# H616 register map
Vendor: Allwinner; Series: H616; File version: 0.1
CPU: other 0, little endian, MPU, no FPU, 0 interrupt priority bits
Registers are 32-bit, read-write, reset 0x0 unless marked. A register's access mark holds for its fields unless they carry their own. Offsets are from the block's base; [hi:lo] are bit positions; {n}, {i} and the like mark numbered series; 'fields as' and 'values as' point back to an identical list.

## RTC
Base 0x07000000
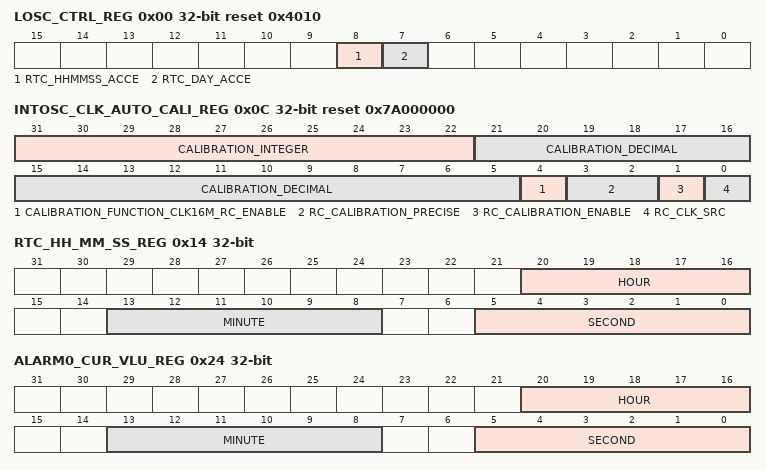
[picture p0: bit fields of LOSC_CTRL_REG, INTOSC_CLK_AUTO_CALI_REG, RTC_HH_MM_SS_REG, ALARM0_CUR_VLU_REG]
0x00 LOSC_CTRL_REG reset 0x4010 — Low Oscillator Control Register
  [8] RTC_HHMMSS_ACCE — RTC HH-MM-SS access After writing the RTC HH-MM-SS Register, this bit is set and it will be cleared until the real writing operation is finished. After writing the RTC HH-MM-SS Register, the RTC HH-MM-SS Register will be refreshed for at most one second.
  [7] RTC_DAY_ACCE — RTC DAY access After writing the RTC DAY register, this bit is set and it will be cleared until the real writing operation is finished. After writing the RTC DAY register, the DAY register will be refreshed for at most one second.
0x08 INTOSC_CLK_PRESCAL_REG reset 0xF — Internal OSC Clock Prescalar Register
  [4:0] INTOSC_32K_CLK_PRESCAL — Internal OSC 32K Clock Prescalar value N. The clock output = Internal RC/32/N. 00000: 1 00001: 2 00002: 3 ...... 11111: 32
    0=_1; 1=_2; 2=_3; 31=_32
0x0C INTOSC_CLK_AUTO_CALI_REG reset 0x7A000000 — Internal OSC Clock Auto Calibration Register
  [31:22] CALIBRATION_INTEGER ro — 32k calibration integer divider factor
  [21:5] CALIBRATION_DECIMAL ro — 32k calibration decimal divider factor
  [4] CALIBRATION_FUNCTION_CLK16M_RC_ENABLE — Calibration function Clk16M_RC_enable 0: Auto gating 1: Soft bypass
    0=Auto gating; 1=Soft bypass
  [3:2] RC_CALIBRATION_PRECISE — RC Calibration Precise Selection 00: 1ms calibration precise 01: 16ms calibration precise 10: 128ms calibration precise
    0=1ms calibration precise; 1=16ms calibration precise; 2=128ms calibration precise
  [1] RC_CALIBRATION_ENABLE — RC Calibration Enable 0: Close Calibration circuit 1: Open Calibration circuit
    0=Close Calibration circuit; 1=Open Calibration circuit
  [0] RC_CLK_SRC — RC CLK SRC SEL Select the RTC 32k clock source from normal RC or Calibrated RC 0: Normal RC 1: Calibrated RC
    0=Normal RC; 1=Calibrated RC
0x10 RTC_DAY_REG reset not defined — RTC Year-Month-Day Register
  [15:0] DAY — Day Range from 0~65535.
0x14 RTC_HH_MM_SS_REG reset not defined — RTC Hour-Minute-Second Register
  [20:16] HOUR — Range from 0~23
  [13:8] MINUTE — Range from 0~59
  [5:0] SECOND — Range from 0~59
0x20 ALARM0_COUNTER_REG — Alarm 0 Counter Register
  [15:0] ALARM0_COUNTER — Alarm 0 Counter is based on Day.
0x24 ALARM0_CUR_VLU_REG reset not defined — Alarm 0 Counter Current Value Register
  fields as RTC_HH_MM_SS_REG
0x28 ALARM0_ENABLE_REG — Alarm 0 Enable Register
  [0] ALM_0_EN — Alarm 0 Enable If this bit is set to `1`, the valid bits of Alarm 0 Counter Register will down count to zero, and the alarm pending bit will be set to `1`. 0: Disable 1: Enable
    0=Disable; 1=Enable
0x2C ALARM0_IRQ_EN — Alarm 0 IRQ Enable Register
  [0] ALARM0_IRQ_EN — Alarm 0 IRQ Enable 0: Disable 1: Enable
    0=Disable; 1=Enable
0x30 ALARM0_IRQ_STA_REG — Alarm 0 IRQ Status Register
  [0] ALARM0_IRQ_PEND write-1-clears — Alarm 0 IRQ Pending bit 0: No effect 1: Pending, alarm 0 counter value is reached If alarm 0 irq enable is set to 1, the pending bit will be sent to the interrupt controller.
    0=No_effect; 1=Pending, alarm 0 counter value is reached If alarm 0 irq enable is set to 1, the pending bit will be sent to the interrupt controller
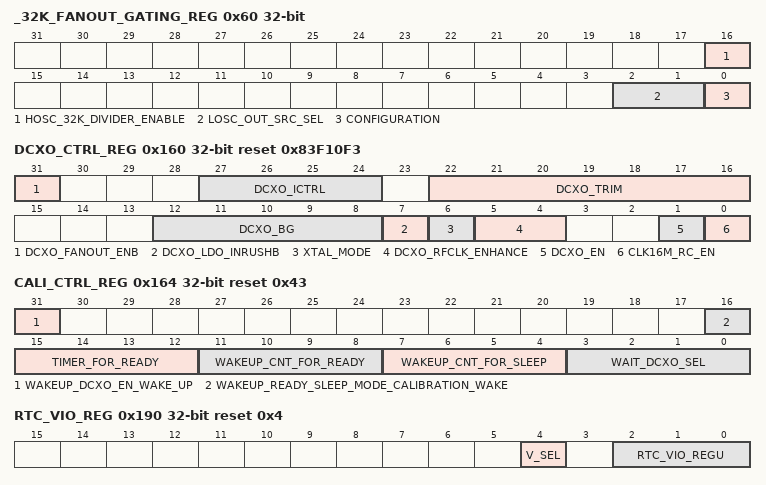
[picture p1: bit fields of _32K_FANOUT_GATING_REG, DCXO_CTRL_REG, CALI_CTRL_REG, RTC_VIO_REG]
0x60 _32K_FANOUT_GATING_REG
  [16] HOSC_32K_DIVIDER_ENABLE — HOSC_32K_DIVIDER_ENABLE 1: enable the hosc 24m to 32k divider circuit 0: disable the hosc 24m to 32k divider circuit
    1=enable the hosc 24m to 32k divider circuit; 0=disable the hosc 24m to 32k divider circuit
  [2:1] LOSC_OUT_SRC_SEL — LOSC_OUT_SRC_SEL 00:RTC_32K(select by RC_CLK_SRC_SEL) 01: Peripll divided 32K 10: HOSC divided 32K
    1=Peripll divided 32K; 2=HOSC (HOSC divided 32K)
  [0] CONFIGURATION — 32K_FANOUT_GATING Configuration of 32k output, and no 32k output by default. 0: Mask LOSC output gating 1: Enable LOSC output gating
    0=Mask LOSC output gating; 1=Enable LOSC output gating
{0x100+4i} GP_DATA_REGN[{i}] (i=0..15) — GP_DATA_REGN[{i}]
  [31:0] GP_DATA — Data [31:0]
0x160 DCXO_CTRL_REG reset 0x83F10F3 — DCXO Control Register
  [31] DCXO_FANOUT_ENB — 0: enable DCXO wake up function 1: disable DCXO wake up function
    0=enable DCXO wake up function; 1=disable DCXO wake up function
  [27:24] DCXO_ICTRL — DCXO current control value
  [22:16] DCXO_TRIM — DCXO cap array value Capacity cell is 55fF
  [12:8] DCXO_BG — DCXO bandgap output voltage
  [7] DCXO_LDO_INRUSHB — DCXO LDO driving capacity signal, active high
  [6] XTAL_MODE — Xtal mode enable signal, active high 0: For external clk input mode 1: For normal mode
    0=For external clk input mode; 1=For_normal_mode
  [5:4] DCXO_RFCLK_ENHANCE — DCXO rfclk enhance Enhance driving capacity of output OUT_RF_REFCLK, 0x0 for 5pF, 0x1 for 10pF, 0x2 for 15pF, 0x3 for 20pF.
  [1] DCXO_EN — DCXO enable 1: Enable 0: Disable
    1=Enable; 0=Disable
  [0] CLK16M_RC_EN — 1: Enable 0: Disable The related register configuration is necessary to ensure the reset debounce circuit has a stable clock source. The first time SoC starts up, by default, the reset debounce circuit of SoC uses 32K divided by RC16M. In power-off, software reads the related bit to ensure whether EXT32K is working normally, if it is normal, first switch the clock source of debounce circuit to EXT32K, then close RC16M. Without EXT32K scenario or external RTC scenario, software confirms firstly whether EXT32K is working normally before switching, or software does not close RC16M.
    1=Enable; 0=Disable The related register configuration is necessary to ensure the reset debounce circuit has a stable clock source. The first time SoC starts up, by default, the reset debounce circuit of SoC uses 32K divided by RC16M. In power-off, software reads the related bit to ensure whether EXT32K is working normally, if it is normal, first switch the clock source of debounce circuit to EXT32K, then close RC16M. Without EXT32K scenario or external RTC scenario, software confirms firstly whether EXT32K is working normally before switching, or software does not close RC16M.
0x164 CALI_CTRL_REG reset 0x43
  [31] WAKEUP_DCXO_EN_WAKE_UP — WAKEUP_DCXO_EN Wake up DCXO circuit enable.
  [16] WAKEUP_READY_SLEEP_MODE_CALIBRATION_WAKE — WAKEUP_READY_SLEEP_MODE Calibration wake up ready sleep mode, it must be set before the WAKEUP_DCXO_EN is set to 1. 0: Disable 1: Enable
    0=Disable; 1=Enable
  [15:12] TIMER_FOR_READY — TIMER FOR READY SLEEP Total timer for ready sleep 0x00: 15s 0x01: 30s 0x02: 45s 0x03: 60s 0x04: 90s 0x05: 120s 0x06: 150s Others: /
    0=_15s; 1=_30s; 2=_45s; 3=_60s; 4=_90s; 5=_120s; 6=150s Others: /
  [11:8] WAKEUP_CNT_FOR_READY — WAKEUP_CNT FOR READY SLEEP Wake up counter for ready sleep 0x00: 250ms 0x01: 500ms 0x02: 750ms 0x03: 1s 0x04: 1.25s 0x05: 1.5s 0x06: 1.75s 0x07: 2s 0x08: 2.25s 0x09: 2.5s 0x0A: 2.75s 0x0B: 3s 0x0C: 3.25s 0x0D: 3.5s 0x0E: 3.75s 0x0F: 4s
    0=_250ms; 1=_500ms; 2=_750ms; 3=_1s; 4=_1_point_25s (1.25s); 5=_1_point_5s (1.5s); 6=_1_point_75s (1.75s); 7=_2s; 8=_2_point_25s (2.25s); 9=_2_point_5s (2.5s); 10=_2_point_75s (2.75s); 11=_3s; 12=_3_point_25s (3.25s); 13=_3_point_5s (3.5s); 14=_3_point_75s (3.75s); 15=_4s
  [7:4] WAKEUP_CNT_FOR_SLEEP — WAKEUP_CNT FOR SLEEP Wake up counter for sleep 0x00: 250ms 0x01: 500ms 0x02: 1s 0x03: 10s 0x04: 60s 0x05: 120s 0x06: 180s 0x07: 240s 0x08: 300s 0x09: 360s 0x0A: 420s 0x0B: 480s 0x0C: 540s 0x0D: 600s 0x0E: 1200s 0x0F: 1800s
    0=_250ms; 1=_500ms; 2=_1s; 3=_10s; 4=_60s; 5=_120s; 6=_180s; 7=_240s; 8=_300s; 9=_360s; 10=_420s; 11=_480s; 12=_540s; 13=_600s; 14=_1200s; 15=_1800s
  [3:0] WAIT_DCXO_SEL — WAIT DCXO SEL Select for DCXO active after DCXO enable 0x0: 1ms 0x1:2ms 0x2:3ms 0x3:4ms ... 0xF: 16ms
    0=1ms 0x1:2ms 0x2:3ms 0x3:4ms ; 15=_16ms
0x190 RTC_VIO_REG reset 0x4 — RTC_VIO Regulate Register
  [4] V_SEL — 0: resistance divider 1: band gap
    0=resistance divider; 1=band gap
  [2:0] RTC_VIO_REGU — These bits are useful for regulating the RTC_VIO from 0.6V to 1.3V, and the regulation step is 0.1V. 000: 1.0V 001: 0.6V (the configuration can cause RTC reset) 010: 0.7V 011: 0.8V 100: 0.9V 101: 1.1V 110: 1.2V 111: 1.3V RTC-VIO is provided power for RTC digital part, the default value is 0.9V. After power-on, software sets the field to 0.8V to save power-consumption.
    0=_1_point_0V (1.0V); 1=_0_point_6V (0.6V (the configuration can cause RTC reset)); 2=_0_point_7V (0.7V); 3=_0_point_8V (0.8V); 4=_0_point_9V (0.9V); 5=_1_point_1V (1.1V); 6=_1_point_2V (1.2V); 7=_1_point_3V (1.3V RTC-VIO is provided power for RTC digital part, the default value is 0.9V. After power-on, software sets the field to 0.8V to save power-consumption.)
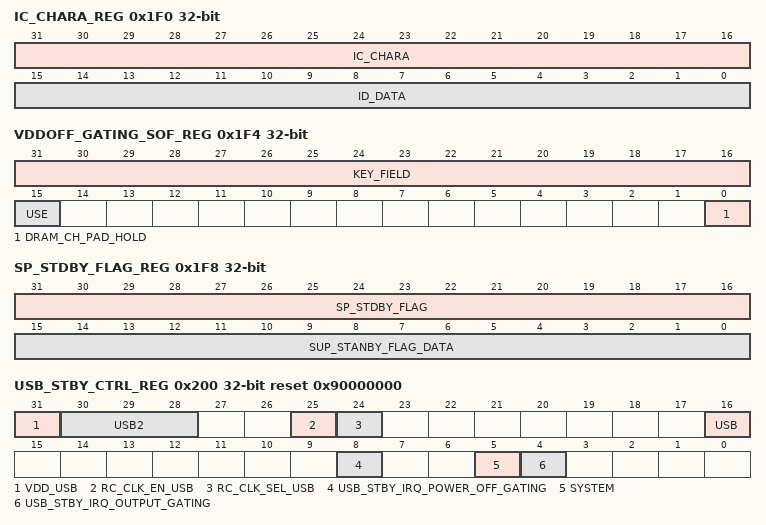
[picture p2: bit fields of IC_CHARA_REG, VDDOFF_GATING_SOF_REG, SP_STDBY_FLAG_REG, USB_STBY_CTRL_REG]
0x1F0 IC_CHARA_REG — IC Characteristic Register
  [31:16] IC_CHARA — Key Field Should be written at value 0x16AA. Writing any other value in this field aborts the write operation.
  [15:0] ID_DATA — Return 0x16AA only if the KEY_FIELD is set as 0x16AA when read those bits, otherwise return 0x0.
0x1F4 VDDOFF_GATING_SOF_REG — VDD To RTC Isolation Software Control Register
  [31:16] KEY_FIELD wo — Key Field This field should be filled with 0x16AA, and then the bit15 can be configured.
  [15] USE wo — When use vdd_sys to RTC isolation software control, write this bit to 1, it will only be cleared by resetb release.
  [0] DRAM_CH_PAD_HOLD — Hold the pad of DRAM channel 0:not hold 1:hold dram Pad This bit should be set to 1 before VDD_SYS power off while it should be set to 0 after the VDD_SYS power on.
0x1F8 SP_STDBY_FLAG_REG — Super Standby Flag Register
  [31:16] SP_STDBY_FLAG — Key Field Any value can be written and read back in the key field, but if the values are not appropriate, the lower 16 bits will not change in this register. Only fellow the appropriate process, the super standby flag can be written in the lower 16 bits.
  [15:0] SUP_STANBY_FLAG_DATA — When system is turned on, the low 16 bits of the value in the Super Standby Flag Register should be 0x0. If software programmer wants to write correct super standby flag ID in low 16 bits, the high 16 bits should be written with 0x16AA at first. Then, software programmer must write 0xAA16XXXX in the Super Standby Flag Register, the `XXXX` means the correct super standby flag ID.
0x1FC SP_STDBY_SOFT_ENTRY_REG — Super Standby Software Entry Register
  [31:0] CPU — software entry register when acting from supper standby.
0x200 USB_STBY_CTRL_REG reset 0x90000000 — USB Standby Control Register
  [31] VDD_USB — power source sel 1: VDD_USB power from ldo 0: VDD_USB power from pin
    1=power_from_ldo (VDD_USB power from ldo); 0=power_from_pin (VDD_USB power from pin)
  [30:28] USB2 — LDO output power level select: 000: 0.87V 001: 0.9V 010: 0.94V 011: 0.97V 100:1.01V 101:1.05V 110:1.08V 111:1.11V
    0=_0_point_87V (0.87V); 1=_0_point_9V (0.9V); 2=_0_point_94V (0.94V); 3=_0_point_97V (0.97V 100:1.01V 101:1.05V 110:1.08V 111:1.11V)
  [25] RC_CLK_EN_USB — 0: Disable 1: Enable
    0=Disable; 1=Enable
  [24] RC_CLK_SEL_USB — SCLK_USBPHY, EHCI_HCLK and OHCI_SCLK Clock Source Select. RC16M clock is selected only in USB standby mode if necessary. 0: SCLK_USBPHY is from OSC24M, EHCI_HCLK and OHCI_HCLK are from Hclk 1: SCLK_USBPHY, EHCI_HCLK and OHCI_SCLK are from RC16M
    0=from (SCLK_USBPHY is from OSC24M, EHCI_HCLK and OHCI_HCLK are from Hclk); 1=SCLK_USBPHY_comma__EHCI_HCLK_and (SCLK_USBPHY, EHCI_HCLK and OHCI_SCLK are from RC16M)
  [16] USB — POWER OFF GATING Gating the VDD_SYS to VDD_USB signal in USB standby mode. It must be set to 1 before entering USB standby mode and set to 0 when exiting Normal mode. 0: disable 1: enable
    0=disable; 1=enable
  [8] USB_STBY_IRQ_POWER_OFF_GATING — Gating the USB standby irq signal to RTC module in Super Standby mode when USB module is power off. It must be set to 1 in Super Standby mode and must set to 0 in other mode. 0: disable 1: enable
    0=disable; 1=enable
  [5] SYSTEM — STANDBY IRQ OUTPUT GATING Mask the SYS standby irq output to nmi pad when SoC is going to USB standby mode or Super standby mode. 0: disable irq output 1: enable irq output
    0=disable irq output; 1=enable irq output
  [4] USB_STBY_IRQ_OUTPUT_GATING — Mask the USB standby irq output to nmi pad. It must be set to 1 in USB standby mode and set to 0 in other mode. 0: disable irq output 1: enable irq output
    0=disable irq output; 1=enable irq output
0x204 EFUSE_HV_PWRSWT_CTRL_REG — Efuse High Voltage Power Switch Control Register
  [0] EFUSE_1_8V_POWER_SWITCH_CONTROL — 1: open power switch 0: close power switch Before programming efuse, the bit need be set to 1.
    1=open power switch; 0=close power switch Before programming efuse, the bit need be set to 1
0x210 CRY_CONFIG_REG — Crypt Configuration Register
  [15:0] KEY_FIELD — Key Field If you want to read or write Crypt Key Register/Crypt Enable Register, you should write 0x1689 in these bits.
0x214 CRY_KEY_REG — Crypt Key Register
  [31:0] CRY_KEY — Crypto Key
0x218 CRY_EN_REG — Crypt Enable Register
  [0] CRY_EN — Crypto Enable
